# CC2538NF53 register map
File version: 1.0
CPU: CM3 1.0, other endian, MPU, FPU, 3 interrupt priority bits
Registers are 32-bit, read-write, reset 0x0 unless marked. A register's access mark holds for its fields unless they carry their own. Offsets are from the block's base; [hi:lo] are bit positions; {n}, {i} and the like mark numbered series.

## UDMA — Register fields should be considered static unless otherwise noted as dynamic.
Base 0x400FF000
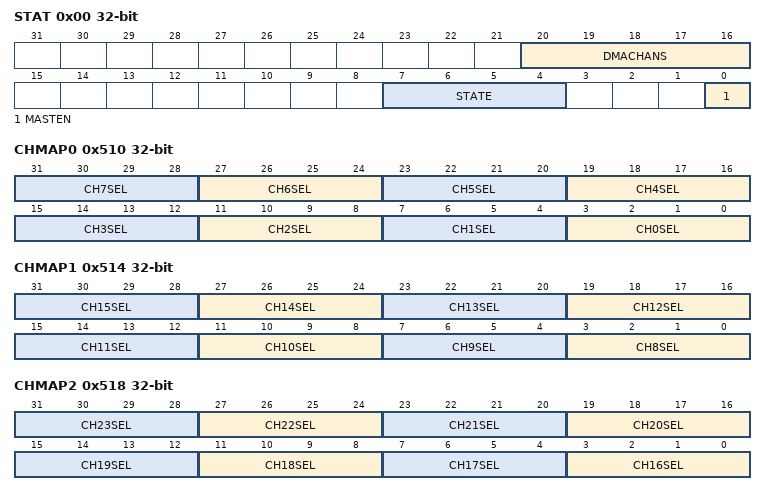
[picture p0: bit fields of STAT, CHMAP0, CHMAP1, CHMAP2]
0x00 STAT — DMA status The STAT register returns the status of the uDMA controller. This register cannot be read when the uDMA controller is in the reset state.
  [20:16] DMACHANS — [20:16] Available uDMA channels minus 1 This field contains a value equal to the number of uDMA channels the uDMA controller is configured to use, minus one. The value of 0x1F corresponds to 32 uDMA channels.
  [7:4] STATE — [7:4] Control state machine status This field shows the current status of the control state-machine. Status can be one of the following: 0x0: Idle 0x1: Reading channel controller data 0x2: Reading source end pointer 0x3: Reading destination end pointer 0x4: Reading source data 0x5: Writing destination data 0x6: Waiting for uDMA request to clear 0x7: Writing channel controller data 0x8: Stalled 0x9: Done 0xA-0xF: Undefined
  [0] MASTEN — [0:0] Master enable status 0: The uDMA controller is disabled. 1: The uDMA controller is enabled.
0x04 CFG — DMA configuration The CFG register controls the configuration of the uDMA controller.
  [0] MASTEN — [0:0] Controller master enable 0: Disables the uDMA controller. 1: Enables the uDMA controller.
0x08 CTLBASE — DMA channel control base pointer The CTLBASE register must be configured so that the base pointer points to a location in system memory. The amount of system memory that must be assigned to the uDMA controller depends on the number of uDMA channels used and whether the alternate channel control data structure is used. See Section 10.2.5 for details about the Channel Control Table. The base address must be aligned on a 1024-byte boundary. This register cannot be read when the uDMA controller is in the reset state.
  [31:10] ADDR — [31:10] Channel control base address This field contains the pointer to the base address of the channel control table. The base address must be 1024-byte alligned.
0x0C ALTBASE — DMA alternate channel control base pointer The ALTBASE register returns the base address of the alternate channel control data. This register removes the necessity for application software to calculate the base address of the alternate channel control structures. This register cannot be read when the uDMA controller is in the reset state.
  [31:0] ADDR — [31:0] Alternate channel address pointer This field provides the base address of the alternate channel control structures.
0x10 WAITSTAT — DMA channel wait-on-request status This read-only register indicates that the uDMA channel is waiting on a request. A peripheral can hold off the uDMA from performing a single request until the peripheral is ready for a burst request to enhance the uDMA performance. The use of this feature is dependent on the design of the peripheral and is not controllable by software in any way. This register cannot be read when the uDMA controller is in the reset state.
  [31:0] WAITREQ — [31:0] Channel [n] wait status These bits provide the tchannel wait-on-request status. Bit 0 corresponds to channel 0. 1: The corresponding channel is waiting on a request. 0: The corresponding channel is not waiting on a request.
0x14 SWREQ — DMA channel software request Each bit of the SWREQ register represents the corresponding uDMA channel. Setting a bit generates a request for the specified uDMA channel.
  [31:0] SWREQ — [31:0] Channel [n] software request These bits generate software requests. Bit 0 corresponds to channel 0. 1: Generate a software request for the corresponding channel 0: No request generated These bits are automatically cleared when the software request has been completed.
0x18 USEBURSTSET — DMA channel useburst set Each bit of the USEBURSTSET register represents the corresponding uDMA channel. Setting a bit disables the channel single request input from generating requests, configuring the channel to only accept burst requests. Reading the register returns the status of USEBURST. If the amount of data to transfer is a multiple of the arbitration (burst) size, the corresponding SET[n] bit is cleared after completing the final transfer. If there are fewer items remaining to transfer than the arbitration (burst) size, the uDMA controller automatically clears the corresponding SET[n] bit, allowing the remaining items to transfer using single requests. To resume transfers using burst requests, the corresponding bit must be set again. A bit must not be set if the corresponding peripheral does not support the burst request model.
  [31:0] SET — [31:0] Channel [n] useburst set 0: uDMA channel [n] responds to single or burst requests. 1: uDMA channel [n] responds only to burst requests. Bit 0 corresponds to channel 0. This bit is automatically cleared as described above. A bit can also be manually cleared by setting the corresponding CLR[n] bit in the DMAUSEBURSTCLR register.
0x1C USEBURSTCLR — DMA channel useburst clear Each bit of the USEBURSTCLR register represents the corresponding uDMA channel. Setting a bit clears the corresponding SET[n] bit in the USEBURSTSET register.
  [31:0] CLR — [31:0] Channel [n] useburst clear 0: No effect 1: Setting a bit clears the corresponding SET[n] bit in the DMAUSEBURSTSET register meaning that uDMA channel [n] responds to single and burst requests.
0x20 REQMASKSET — DMA channel request mask set Each bit of the REQMASKSET register represents the corresponding uDMA channel. Setting a bit disables uDMA requests for the channel. Reading the register returns the request mask status. When a uDMA channel request is masked, that means the peripheral can no longer request uDMA transfers. The channel can then be used for software-initiated transfers.
  [31:0] SET — [31:0] Channel [n] request mask set 0: The peripheral associated with channel [n] is enabled to request uDMA transfers 1: The peripheral associated with channel [n] is not able to request uDMA transfers. Channel [n] may be used for software-initiated transfers. Bit 0 corresponds to channel 0. A bit can only be cleared by setting the corresponding CLR[n] bit in the DMAREQMASKCLR register.
0x24 REQMASKCLR — DMA channel request mask clear Each bit of the REQMASKCLR register represents the corresponding uDMA channel. Setting a bit clears the corresponding SET[n] bit in the REQMASKSET register.
  [31:0] CLR — [31:0] Channel [n] request mask clear 0: No effect 1: Setting a bit clears the corresponding SET[n] bit in the DMAREQMASKSET register meaning that the peripheral associated with channel [n] is enabled to request uDMA transfers.
0x28 ENASET — DMA channel enable set Each bit of the ENASET register represents the corresponding uDMA channel. Setting a bit enables the corresponding uDMA channel. Reading the register returns the enable status of the channels. If a channel is enabled but the request mask is set (REQMASKSET), then the channel can be used for software-initiated transfers.
  [31:0] SET — [31:0] Channel [n] enable set 0: uDMA channel [n] is disabled 1: uDMA channel [n] is enabled Bit 0 corresponds to channel 0. A bit can only be cleared by setting the corresponding CLR[n] bit in the DMAENACLR register.
0x2C ENACLR — DMA channel enable clear Each bit of the ENACLR register represents the corresponding uDMA channel. Setting a bit clears the corresponding SET[n] bit in the ENASET register.
  [31:0] CLR — [31:0] Channel [n] enable clear 0: No effect 1: Setting a bit clears the corresponding SET[n] bit in the DMAENASET register meaning that channel [n] is disabled for uDMA transfers. Note: The controller disables a channel when it completes the uDMA cycle.
0x30 ALTSET — DMA channel primary alternate set Each bit of the ALTSET register represents the corresponding uDMA channel. Setting a bit configures the uDMA channel to use the alternate control data structure. Reading the register returns the status of which control data structure is in use for the corresponding uDMA channel.
  [31:0] SET — [31:0] Channel [n] alternate set 0: uDMA channel [n] is using the primary control structure 1: uDMA channel [n] is using the alternate control structure Bit 0 corresponds to channel 0. A bit can only be cleared by setting the corresponding CLR[n] bit in the DMAALTCLR register. Note: For Ping-Pong and Scatter-Gather cycle types, the uDMA controller automatically sets these bits to select the alternate channel control data structure.
0x34 ALTCLR — DMA channel primary alternate clear Each bit of the ALTCLR register represents the corresponding uDMA channel. Setting a bit clears the corresponding SET[n] bit in the ALTSET register.
  [31:0] CLR — [31:0] Channel [n] alternate clear 0: No effect 1: Setting a bit clears the corresponding SET[n] bit in the DMAALTSET register meaning that channel [n] is using the primary control structure. Note: For Ping-Pong and Scatter-Gather cycle types, the uDMA controller automatically sets these bits to select the alternate channel control data structure.
0x38 PRIOSET — DMA channel priority set Each bit of the PRIOSET register represents the corresponding uDMA channel. Setting a bit configures the uDMA channel to have a high priority level. Reading the register returns the status of the channel priority mask.
  [31:0] SET — [31:0] Channel [n] priority set 0: uDMA channel [n] is using the default priority level 1: uDMA channel [n] is using a high priority level Bit 0 corresponds to channel 0. A bit can only be cleared by setting the corresponding CLR[n] bit in the DMAPRIOCLR register.
0x3C PRIOCLR — DMA channel priority clear Each bit of the DMAPRIOCLR register represents the corresponding uDMA channel. Setting a bit clears the corresponding SET[n] bit in the PRIOSET register.
  [31:0] CLR — [31:0] Channel [n] priority clear 0: No effect 1: Setting a bit clears the corresponding SET[n] bit in the DMAPRIOSET register meaning that channel [n] is using the default priority level.
0x4C ERRCLR — DMA bus error clear The ERRCLR register is used to read and clear the uDMA bus error status. The error status is set if the uDMA controller encountered a bus error while performing a transfer. If a bus error occurs on a channel, that channel is automatically disabled by the uDMA controller. The other channels are unaffected.
  [0] ERRCLR — [0:0] uDMA bus error status 0: No bus error is pending 1: A bus error is pending This bit is cleared by writing 1 to it.
0x500 CHASGN — DMA channel assignment Each bit of the CHASGN register represents the corresponding uDMA channel. Setting a bit selects the secondary channel assignment as specified in the section "Channel Assignments"
  [31:0] CHASGN — [31:0] Channel [n] assignment select 0: Use the primary channel assignment 1: Use the secondary channel assignment
0x504 CHIS — DMA channel interrupt status Each bit of the CHIS register represents the corresponding uDMA channel. A bit is set when that uDMA channel causes a completion interrupt. The bits are cleared by writing 1.
  [31:0] CHIS — [31:0] Channel [n] interrupt status 0: The corresponding uDMA channel has not caused an interrupt. 1: The corresponding uDMA channel has caused an interrupt. This bit is cleared by writing 1 to it.
0x510 CHMAP0 — DMA channel map select 0 Each 4-bit field of the CHMAP0 register configures the uDMA channel assignment as specified in the uDMA channel assignment table in the "Channel Assignments" section.
  [4n+3:4n] CH{n}SEL (n=0..7) — [{4n+3}:{4n}] uDMA channel {n} source select See section titled "Channel Assignments" in Micro Direct Memory Access chapter.
0x514 CHMAP1 — DMA channel map select 1 Each 4-bit field of the CHMAP1 register configures the uDMA channel assignment as specified in the uDMA channel assignment table in the "Channel Assignments" section.
  [4n-29:4n-32] CH{n}SEL (n=8..15) — [{4n-29}:{4n-32}] uDMA channel {n} source select See section titled "Channel Assignments" in Micro Direct Memory Access chapter.
0x518 CHMAP2 — DMA channel map select 2 Each 4-bit field of the CHMAP2 register configures the uDMA channel assignment as specified in the uDMA channel assignment table in the "Channel Assignments" section.
  [4n-61:4n-64] CH{n}SEL (n=16..23) — [{4n-61}:{4n-64}] uDMA channel {n} source select See section titled "Channel Assignments" in Micro Direct Memory Access chapter.
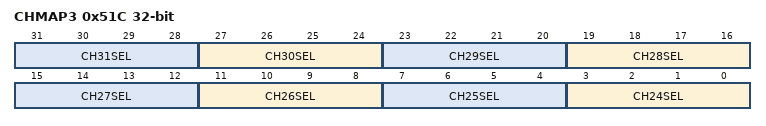
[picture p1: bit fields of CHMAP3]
0x51C CHMAP3 — DMA channel map select 3 Each 4-bit field of the CHMAP3 register configures the uDMA channel assignment as specified in the uDMA channel assignment table in the "Channel Assignments" section.
  [4n-93:4n-96] CH{n}SEL (n=24..31) — [{4n-93}:{4n-96}] uDMA channel {n} source select See section titled "Channel Assignments" in Micro Direct Memory Access chapter.
